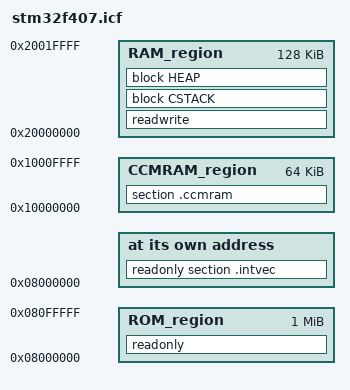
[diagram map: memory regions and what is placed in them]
/*******************************************************************************
 * File Name          : stm32f407.icf
 * Description        : IAR linker configuration file for STM32F407VG
 *                      1024KB Flash, 128KB RAM, 64KB CCM RAM
 * Author             : Nexus Team
 *******************************************************************************
 * Copyright (c) 2026 Nexus Team
 *
 * This linker configuration file defines memory layout and section placement
 * for STM32F407VG microcontroller using IAR EWARM toolchain.
 ******************************************************************************/

/*******************************************************************************
 * Memory Regions
 ******************************************************************************/

/* Flash memory */
define symbol __ICFEDIT_region_ROM_start__ = 0x08000000;
define symbol __ICFEDIT_region_ROM_end__   = 0x080FFFFF;  /* 1MB */

/* RAM memory */
define symbol __ICFEDIT_region_RAM_start__ = 0x20000000;
define symbol __ICFEDIT_region_RAM_end__   = 0x2001FFFF;  /* 128KB */

/* CCM RAM memory */
define symbol __ICFEDIT_region_CCMRAM_start__ = 0x10000000;
define symbol __ICFEDIT_region_CCMRAM_end__   = 0x1000FFFF;  /* 64KB */

/*******************************************************************************
 * Stack and Heap Sizes
 ******************************************************************************/

define symbol __ICFEDIT_size_cstack__ = 0x400;  /* 1KB stack */
define symbol __ICFEDIT_size_heap__   = 0x200;  /* 512B heap */

/*******************************************************************************
 * Memory Region Definitions
 ******************************************************************************/

define memory mem with size = 4G;

define region ROM_region      = mem:[from __ICFEDIT_region_ROM_start__   to __ICFEDIT_region_ROM_end__];
define region RAM_region      = mem:[from __ICFEDIT_region_RAM_start__   to __ICFEDIT_region_RAM_end__];
define region CCMRAM_region   = mem:[from __ICFEDIT_region_CCMRAM_start__ to __ICFEDIT_region_CCMRAM_end__];

/*******************************************************************************
 * Stack and Heap Blocks
 ******************************************************************************/

define block CSTACK    with alignment = 8, size = __ICFEDIT_size_cstack__   { };
define block HEAP      with alignment = 8, size = __ICFEDIT_size_heap__     { };

/*******************************************************************************
 * Initialization
 ******************************************************************************/

initialize by copy { readwrite };
do not initialize  { section .noinit };

/*******************************************************************************
 * Section Placement
 ******************************************************************************/

/* Vector table must be at the beginning of Flash */
place at address mem:__ICFEDIT_region_ROM_start__ { readonly section .intvec };

/* Code and constants in Flash */
place in ROM_region   { readonly };

/* Initialized and uninitialized data in RAM */
place in RAM_region   { readwrite,
                        block CSTACK,
                        block HEAP };

/* CCM RAM sections (optional) */
place in CCMRAM_region { section .ccmram };

/*******************************************************************************
 * End of linker configuration file
 ******************************************************************************/
